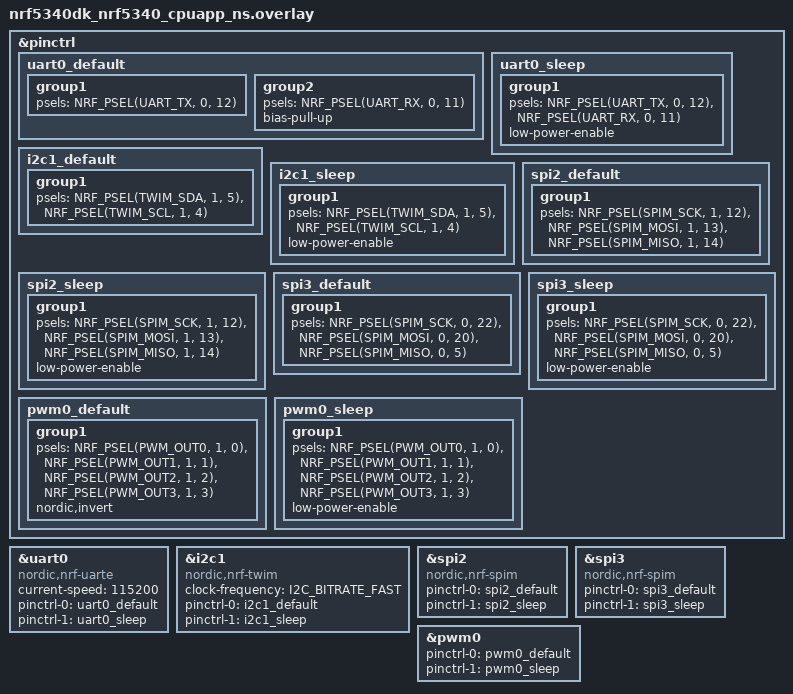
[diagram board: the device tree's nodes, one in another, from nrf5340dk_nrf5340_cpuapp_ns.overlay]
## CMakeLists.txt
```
#
# Copyright (c) 2019 Nordic Semiconductor ASA
#
# SPDX-License-Identifier: LicenseRef-BSD-5-Clause-Nordic
#

cmake_minimum_required(VERSION 3.20.0)

if (EXISTS "${CMAKE_CURRENT_SOURCE_DIR}/spm.conf")
  set(spm_CONF_FILE
    prj.conf
    ${CMAKE_CURRENT_LIST_DIR}/spm.conf
  )
endif()

if (EXISTS "${CMAKE_CURRENT_SOURCE_DIR}/mcuboot.conf")
  set(mcuboot_CONF_FILE
    prj.conf
    ${CMAKE_CURRENT_LIST_DIR}/mcuboot.conf
  )
endif()

find_package(Zephyr REQUIRED HINTS $ENV{ZEPHYR_BASE})
project(E2)
zephyr_compile_definitions(PROJECT_NAME=${PROJECT_NAME})

# NORDIC SDK APP START
target_sources(app PRIVATE src/main.c)
# NORDIC SDK APP END

# Include source directory
target_include_directories(app PRIVATE src)
target_include_directories(app PRIVATE $ENV{ZEPHYR_BASE}/subsys/fs/nvs)

# Application directories
add_subdirectory(src/datetime)
add_subdirectory(src/font)
add_subdirectory(src/image)
add_subdirectory(src/lcd)
add_subdirectory(src/key)
add_subdirectory(src/settings)
add_subdirectory(src/inner_flash)
add_subdirectory(src/external_flash)
add_subdirectory(src/uart_ble)
add_subdirectory(src/screen)
add_subdirectory(src/pmu)
add_subdirectory(src/codetrans)
add_subdirectory(src/communicate)
add_subdirectory(src/ucs2)
add_subdirectory(src/logger)

add_subdirectory_ifdef(CONFIG_PPG_SUPPORT src/ppg)
add_subdirectory_ifdef(CONFIG_ECG_SUPPORT src/ecg)
add_subdirectory_ifdef(CONFIG_BUZZER_SUPPORT src/buzzer)
add_subdirectory_ifdef(CONFIG_WATCHDOG src/watchdog)
add_subdirectory_ifdef(CONFIG_FACTORY_TEST_SUPPORT src/factory_test)
```

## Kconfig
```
#
# Copyright (c) 2018 Nordic Semiconductor ASA
#
# SPDX-License-Identifier: LicenseRef-BSD-5-Clause-Nordic
#
choice LOG_MODE
	default LOG_MODE_IMMEDIATE
endchoice

menu "GPS"
config GPS_SUPPORT
	bool "gps support"
	default n
endmenu #GPS

menu "GNSS"
choice
	default GNSS_SAMPLE_MODE_CONTINUOUS
	prompt "Select GNSS operation mode"

config GNSS_SAMPLE_MODE_CONTINUOUS
	bool "Continuous tracking"

config GNSS_SAMPLE_MODE_PERIODIC
	bool "Periodic fixes"

config GNSS_SAMPLE_MODE_TTFF_TEST
	bool "Time-to-first-fix (TTFF) test mode"
	select GNSS_SAMPLE_NMEA_ONLY
endchoice

if GNSS_SAMPLE_MODE_PERIODIC
config GNSS_SAMPLE_PERIODIC_INTERVAL
	int "Fix interval for periodic fixes"
	range 10 65535
	default 120
	help
	  Fix interval (in seconds) for periodic fixes.
config GNSS_SAMPLE_PERIODIC_TIMEOUT
	int "Fix timeout for periodic fixes"
	range 0 65535
	default 120
	help
	  Fix timeout (in seconds) for periodic fixes.
	  If set to zero, GNSS is allowed to run indefinitely until a valid PVT estimate is produced.
endif # GNSS_SAMPLE_MODE_PERIODIC

if GNSS_SAMPLE_MODE_TTFF_TEST
config GNSS_SAMPLE_MODE_TTFF_TEST_COLD_START
	bool "Delete GNSS data before each start (cold start)"
	help
	  When enabled, deletes all stored data from GNSS to force a cold start every time GNSS is started.
config GNSS_SAMPLE_MODE_TTFF_TEST_INTERVAL
	int "Time to wait between TTFF tests in seconds"
	range 1 604800
	default 120
endif # GNSS_SAMPLE_MODE_TTFF_TEST

config GNSS_SAMPLE_NMEA_ONLY
	bool "Output only NMEA strings"
	help
	  Outputs only NMEA strings from the GNSS.

choice
	default GNSS_SAMPLE_ANTENNA_ONBOARD
	prompt "Select which antenna to use for GNSS"

config GNSS_SAMPLE_ANTENNA_ONBOARD
	bool "Use onboard antenna"

config GNSS_SAMPLE_ANTENNA_EXTERNAL
	bool "Use external antenna"
endchoice

config GNSS_SAMPLE_AT_MAGPIO
	string "AT%XMAGPIO command"
	# default "AT\%XMAGPIO=1,0,0,1,1,1574,1577" if BOARD_NRF9160DK_NRF9160_NS
	# default "AT\%XMAGPIO=1,1,1,7,1,746,803,2,698,748,2,1710,2200,3,824,894,4,880,960,5,791,849,7,1565,1586" if BOARD_THINGY91_NRF9160_NS
	default "AT\%XMAGPIO=1,1,1,7,1,746,803,2,698,748,2,1710,2200,3,824,894,4,880,960,5,791,849,7,1565,1586"
	help
	  Defines the AT%XMAGPIO command to be sent to GNSS module. Leave
	  empty if this command should not be sent.

config GNSS_SAMPLE_AT_COEX0
	string "AT%XCOEX0 command"
	# default "AT\%XCOEX0=1,1,1565,1586" if (BOARD_NRF9160DK_NRF9160_NS || BOARD_THINGY91_NRF9160_NS) && GNSS_SAMPLE_ANTENNA_ONBOARD
	# default "AT\%XCOEX0" if (BOARD_NRF9160DK_NRF9160_NS || BOARD_THINGY91_NRF9160_NS) && GNSS_SAMPLE_ANTENNA_EXTERNAL
	default "AT\%XCOEX0=1,1,1565,1586"
	help
	  Defines the AT%XCOEX0 command to be sent to GNSS module. Leave
	  empty if this command should not be sent.

endmenu #GNSS

choice
	default GNSS_SAMPLE_ASSISTANCE_NONE
	prompt "Select whether GNSS assistance is used or not"

config GNSS_SAMPLE_ASSISTANCE_NONE
	bool "Assistance not used"

config GNSS_SAMPLE_ASSISTANCE_NRF_CLOUD
	bool "Use nRF Cloud A-GPS or P-GPS"
	select NRF_CLOUD_REST
	imply NRF_CLOUD_AGPS
	select MODEM_JWT
	select MODEM_INFO
	select DATE_TIME

config GNSS_SAMPLE_ASSISTANCE_SUPL
	bool "Use SUPL A-GPS"
	select SUPL_CLIENT_LIB

config GNSS_SAMPLE_ASSISTANCE_MINIMAL
	bool "Use factory almanac, LTE network time and MCC based location"
	select GNSS_SAMPLE_LTE_ON_DEMAND
	select SETTINGS
	select FCB
	select FLASH
	select FLASH_MAP
endchoice

if !GNSS_SAMPLE_ASSISTANCE_NONE
config GNSS_SAMPLE_LTE_ON_DEMAND
	bool "LTE is activated only when needed to fetch A-GPS data"
	depends on !NRF_CLOUD_PGPS
	help
	  Activates LTE only when it is needed to fetch A-GPS data. This is not supported when
	  P-GPS is enabled.

endif # !GNSS_SAMPLE_ASSISTANCE_NONE

if GNSS_SAMPLE_ASSISTANCE_SUPL
config GNSS_SAMPLE_SUPL_HOSTNAME
	string "SUPL server hostname"
	default "supl.google.com"
	help
	  SUPL server hostname.

config GNSS_SAMPLE_SUPL_PORT
	int "SUPL server port number"
	range 0 65535
	default 7276
	help
	  SUPL server port number.
endif # GNSS_SAMPLE_ASSISTANCE_SUPL

if GNSS_SAMPLE_MODE_CONTINUOUS
choice
	default GNSS_SAMPLE_POWER_SAVING_DISABLED
	prompt "Select GNSS power saving mode (duty-cycling)"

config GNSS_SAMPLE_POWER_SAVING_DISABLED
	bool "No power saving"

config GNSS_SAMPLE_POWER_SAVING_MODERATE
	bool "Power saving without significant performance degradation"

config GNSS_SAMPLE_POWER_SAVING_HIGH
	bool "Power saving with acceptable performance degradation"
endchoice
endif # GNSS_SAMPLE_MODE_CONTINUOUS

config GNSS_SAMPLE_LOW_ACCURACY
	bool "Allow low accuracy fixes"
	help
	  Allows fixes with lower accuracy.

if GNSS_SAMPLE_ASSISTANCE_MINIMAL && GNSS_SAMPLE_LOW_ACCURACY
config GNSS_SAMPLE_ASSISTANCE_REFERENCE_ALT
	int "Reference altitude for 3-sat first fix in meters"
	range -32767 32767
	default -32767
	help
	  Reference altitude for 3-sat first fix in meters above the reference ellipsoid surface.
	  The default value -32767 implies that reference altitude is not injected.
endif # GNSS_SAMPLE_ASSISTANCE_MINIMAL && GNSS_SAMPLE_LOW_ACCURACY

menu "MQTT simple sample"
config APPLICATION_WORKQUEUE_STACK_SIZE
	int "Application workqueue stack size"
	default 1024

config APPLICATION_WORKQUEUE_PRIORITY
	int "Application workqueue priority"
	default SYSTEM_WORKQUEUE_PRIORITY
	
config MQTT_LOG_PUB_TOPIC
	string "MQTT log publish topic"
	default "device/e2/pushlog"

config MQTT_PUB_TOPIC
	string "MQTT publish topic"
	default "device/e2/pushdata"

config MQTT_SUB_TOPIC
	string "MQTT subscribe topic"
	default "my/subscribe/topic"

config MQTT_CLIENT_ID
	string "MQTT Client ID"
	default "my-client-id"

config MQTT_USER_NAME
	string "MQTT user name"
	default "admin123"
	
config MQTT_PASSWORD
	string "MQTT password"
	default "admin123"

config MQTT_DOMESTIC_BROKER_HOSTNAME
	string "MQTT broker hostname"
	default "mqtt.eclipse.org"

config MQTT_DOMESTIC_BROKER_PORT
	int "MQTT broker port"
	default 1883
	
config MQTT_FOREIGN_BROKER_HOSTNAME
	string "MQTT broker hostname"
	default "mqtt.eclipse.org"

config MQTT_FOREIGN_BROKER_PORT
	int "MQTT broker port"
	default 1883

config MQTT_MESSAGE_BUFFER_SIZE
	int "MQTT message buffer size"
	default 128

config MQTT_PAYLOAD_BUFFER_SIZE
	int "MQTT payload buffer size"
	default 128

config SEC_TAG
	int "Security tag to use for the connection"
	default 16842753

config PEER_VERIFY
	int "Peer verify parameter for mqtt_client"
	default 1
	help
		Set to 0 for VERIFY_NONE, 1 for VERIFY_OPTIONAL, and 2 for VERIFY_REQUIRED.

config MODEM_AUTO_REQUEST_POWER_SAVING_FEATURES
	bool "Auto request power saving features"
	default y

config LTE_EDRX_ENABLE
	bool "Enable LTE enhanced Discontinuous Reception"

config LTE_RAI_ENABLE
	bool "Enable LTE Release Assistance Indication"
endmenu

menu "WATCH DOG"
config WATCHDOG_TIMEOUT_MSEC
	int "Watchdog timeout in milliseconds"
	default 10000
endmenu

menu "ANIMATION"
config ANIMATION_SUPPORT
	bool "animation support"
	default n
endmenu #ANIMATION

menu "ANIMATION"
config ANIMATION_SUPPORT
	bool "animation support"
	default n
endmenu #ANIMATION

menu "TOUCH"
config TOUCH_SUPPORT
	bool "touch support"
	default n
endmenu #TOUCH

menu "WIFI"
config WIFI_SUPPORT
	bool "wifi support"
	default n
endmenu #WIFI

menu "PPG"
config PPG_SUPPORT
	bool "ppg support"
	default n
endmenu #PPG

menu "ECG"
config ECG_SUPPORT
	bool "ecg support"
	default n
endmenu #ECG

menu "IMU"
config IMU_SUPPORT
	bool "imu support"
	default n
config STEP_SUPPORT
	bool "step support"
	default n		
config SLEEP_SUPPORT
	bool "sleep support"
	default n		
config FALL_DETECT_SUPPORT
	bool "fall detect support"
	default n		
endmenu #IMU

menu "AUDIO"
config AUDIO_SUPPORT
	bool "ppg support"
	default n
endmenu #AUDIO

menu "BLE"
config BLE_SUPPORT
	bool "ble support"
	default n
endmenu #BLE

menu "BUZZER"
config BUZZER_SUPPORT
	bool "buzzer support"
	default n
endmenu #BUZZER

menu "SYNC"
config SYNC_SUPPORT
	bool "sync support"
	default n
endmenu #SYNC

menu "TEMPERATURE"
config TEMP_SUPPORT
	bool "temperature support"
	default n
endmenu #TEMPERATURE

menu "CRC"
config CRC_SUPPORT
	bool "crc check support"
	default n
endmenu #CRC

menu "DATA_DOWNLOAD"
config DATA_DOWNLOAD_SUPPORT
	bool "data download support"
	default n
config DATA_DOWNLOAD_HOST_CN
	string "Download host name(cn)"	
config DATA_DOWNLOAD_HOST_HK
	string "Download host name(hk)"	
# IMG	
config IMG_DATA_UPDATE
	bool "img update support"
	default n
config IMG_DATA_DOWNLOAD_FILE
	string "The file to download"

# FONT
config FONT_DATA_UPDATE
	bool "font update support"
	default n
config FONT_DATA_DOWNLOAD_FILE
	string "The file to download"

# PPG
config PPG_DATA_UPDATE
	bool "ppg update support"
	default n
config PPG_DATA_DOWNLOAD_FILE
	string "The file to download"

config USE_HTTPS
	bool
	prompt "Use HTTPS for download"
	depends on DOWNLOAD_CLIENT_TLS	
endmenu #DATA_DOWNLOAD 

menu "IMG_UPDATE"
config DL_TARGET_UI
	bool "img ui update support"
	default n
endmenu #IMG_UPDATE

menu "FOTA_MQTT"
config FOTA_DOWNLOAD_HOST_CN
	string "Download host name(cn)"
config FOTA_DOWNLOAD_HOST_HK
	string "Download host name(hk)"

config FOTA_DOWNLOAD_FILE
	string "The file to download"

config APPLICATION_VERSION
	int "Application version"
	default 1

config USE_HTTPS
	bool
	prompt "Use HTTPS for download"
	depends on DOWNLOAD_CLIENT_TLS
endmenu #FOTA_MQTT

menu "BAT CODE"
config BARCODE_SUPPORT
	bool "bar code support"
	default n
endmenu #BAT CODE

menu "QR CODE"
config QRCODE_SUPPORT
	bool "qr code support"
	default n
endmenu #QR CODE

menu "WRIST CHECK"
config WRIST_CHECK_SUPPORT
	bool "wrist check support"
	default n
endmenu #WRIST CHECK

menu "FACTORY_TEST"
config FACTORY_TEST_SUPPORT
	bool "factory test support"
	default n
endmenu #FACTORY_TEST_SUPPORT

menu "FAST_KEY"
config FAST_KEY_SUPPORT
	bool "fast key support"
	default n
endmenu #FAST_KEY_SUPPORT

menu "ALARM_SUPPORT"
config ALARM_SUPPORT
	bool "alarm support"
	default n
endmenu #ALARM_SUPPORT

menu "Zephyr Kernel"
source "Kconfig.zephyr"
endmenu

module = APPLICATION_MODULE
module-str = Application module
source "subsys/logging/Kconfig.template.log_config"
```

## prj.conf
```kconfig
#
# Copyright (c) 2022 Nordic Semiconductor ASA
#
# SPDX-License-Identifier: LicenseRef-Nordic-5-Clause
#
# General config
CONFIG_NEWLIB_LIBC=y
CONFIG_NEWLIB_LIBC_FLOAT_PRINTF=y
CONFIG_ASSERT=y
CONFIG_REBOOT=y
CONFIG_GPIO=y
CONFIG_TRUSTED_EXECUTION_NONSECURE=y

# Log
CONFIG_LOG=n
CONFIG_USE_SEGGER_RTT=y
CONFIG_LOG_BACKEND_RTT=y
CONFIG_LOG_BACKEND_UART=n
CONFIG_LOG_DEFAULT_LEVEL=4
CONFIG_LOG_MODE_OVERFLOW=y
CONFIG_LOG_BACKEND_RTT_MODE_DROP=y
CONFIG_LOG_BACKEND_SHOW_COLOR=n
CONFIG_LOG_BACKEND_FORMAT_TIMESTAMP=n

# PinCtrl
CONFIG_PINCTRL=y
CONFIG_PINCTRL_NRF=y

# watch dog
CONFIG_WATCHDOG=y
CONFIG_WATCHDOG_TIMEOUT_MSEC=10000

# Fuel gauge
CONFIG_NRF_FUEL_GAUGE=y

# NVS
CONFIG_FLASH=y
CONFIG_FLASH_PAGE_LAYOUT=y
CONFIG_NVS=y
CONFIG_NVS_LOG_LEVEL_DBG=y
CONFIG_MPU_ALLOW_FLASH_WRITE=y

# Console
CONFIG_CONSOLE_SUBSYS=n
CONFIG_CONSOLE_HANDLER=n
CONFIG_CONSOLE_GETCHAR=n
CONFIG_CONSOLE=y
CONFIG_RTT_CONSOLE=y
CONFIG_UART_CONSOLE=n


# Library for buttons and LEDs
CONFIG_DK_LIBRARY=y

# Heap and stacks
CONFIG_HEAP_MEM_POOL_SIZE=16384
CONFIG_MAIN_STACK_SIZE=8192
CONFIG_SYSTEM_WORKQUEUE_STACK_SIZE=2048
CONFIG_HW_STACK_PROTECTION=y

# PWM
CONFIG_PWM=y

# SPI
CONFIG_SPI=y

# I2C
CONFIG_I2C=y

# UART
CONFIG_SERIAL=y
CONFIG_UART_INTERRUPT_DRIVEN=y

# ECG
CONFIG_ECG_SUPPORT=y

# BLE
CONFIG_BLE_SUPPORT=n

# BUZZER
CONFIG_BUZZER_SUPPORT=y

# CRC Check
CONFIG_CRC_SUPPORT=n

# DEVICE POWER MANAGEMENT
CONFIG_PM_DEVICE=y

# Facotry test
CONFIG_FACTORY_TEST_SUPPORT=n
CONFIG_ENTROPY_GENERATOR=y
CONFIG_TEST_RANDOM_GENERATOR=y
```

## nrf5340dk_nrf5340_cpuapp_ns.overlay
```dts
/* SPDX-License-Identifier: Apache-2.0 */

&pinctrl
{
	uart0_default: uart0_default
	{
		group1
		{
			psels = <NRF_PSEL(UART_TX, 0, 12)>;
		};
		group2
		{
			psels = <NRF_PSEL(UART_RX, 0, 11)>;
			bias-pull-up;
		};
	};

	uart0_sleep: uart0_sleep
	{
		group1
		{
			psels = <NRF_PSEL(UART_TX, 0, 12)>,
							<NRF_PSEL(UART_RX, 0, 11)>;
			low-power-enable;
		};
	};
	
	i2c1_default: i2c1_default
	{
		group1
		{
			psels = <NRF_PSEL(TWIM_SDA, 1, 5)>,
							<NRF_PSEL(TWIM_SCL, 1, 4)>;
		};
	};

	i2c1_sleep: i2c1_sleep
	{
		group1
		{
			psels = <NRF_PSEL(TWIM_SDA, 1, 5)>,
							<NRF_PSEL(TWIM_SCL, 1, 4)>;
			low-power-enable;
		};
	};
	
	spi2_default: spi2_default
	{
		group1
		{
			psels = <NRF_PSEL(SPIM_SCK,  1, 12)>,
							<NRF_PSEL(SPIM_MOSI, 1, 13)>,
							<NRF_PSEL(SPIM_MISO, 1, 14)>;
		};
	};

	spi2_sleep: spi2_sleep
	{
		group1
		{
			psels = <NRF_PSEL(SPIM_SCK,  1, 12)>,
							<NRF_PSEL(SPIM_MOSI, 1, 13)>,
							<NRF_PSEL(SPIM_MISO, 1, 14)>;
			low-power-enable;
		};
	};
	
	spi3_default: spi3_default
	{
		group1
		{
			psels = <NRF_PSEL(SPIM_SCK,  0, 22)>,
							<NRF_PSEL(SPIM_MOSI, 0, 20)>,
							<NRF_PSEL(SPIM_MISO, 0, 5)>;
		};
	};

	spi3_sleep: spi3_sleep
	{
		group1
		{
			psels = <NRF_PSEL(SPIM_SCK,  0, 22)>,
							<NRF_PSEL(SPIM_MOSI, 0, 20)>,
							<NRF_PSEL(SPIM_MISO, 0, 5)>;
			low-power-enable;
		};
	};
	
	pwm0_default: pwm0_default
	{
		group1
		{
			psels = <NRF_PSEL(PWM_OUT0,  1, 0)>,
							<NRF_PSEL(PWM_OUT1,  1, 1)>,
							<NRF_PSEL(PWM_OUT2,  1, 2)>,
							<NRF_PSEL(PWM_OUT3,  1, 3)>;
			nordic,invert;
		};
	};

	pwm0_sleep: pwm0_sleep
	{
		group1
		{
			psels = <NRF_PSEL(PWM_OUT0,  1, 0)>,
							<NRF_PSEL(PWM_OUT1,  1, 1)>,
							<NRF_PSEL(PWM_OUT2,  1, 2)>,
							<NRF_PSEL(PWM_OUT3,  1, 3)>;
			low-power-enable;
		};
	};
};


&uart0{
	compatible = "nordic,nrf-uarte";
	status = "okay";
	current-speed = <115200>;
	pinctrl-0 = <&uart0_default>;
	pinctrl-1 = <&uart0_sleep>;
	pinctrl-names = "default", "sleep";
};

&i2c1{
	compatible = "nordic,nrf-twim";
	status = "okay";
	clock-frequency = <I2C_BITRATE_FAST>;
	pinctrl-0 = <&i2c1_default>;
	pinctrl-1 = <&i2c1_sleep>;
	pinctrl-names = "default", "sleep";
};

&spi2{
	compatible = "nordic,nrf-spim";
	status = "okay";
	pinctrl-0 = <&spi2_default>;
	pinctrl-1 = <&spi2_sleep>;
	pinctrl-names = "default", "sleep";
};

&spi3{
	compatible = "nordic,nrf-spim";
	status = "okay";
	pinctrl-0 = <&spi3_default>;
	pinctrl-1 = <&spi3_sleep>;
	pinctrl-names = "default", "sleep";
};

&pwm0{
	status = "okay";
	pinctrl-0 = <&pwm0_default>;
	pinctrl-1 = <&pwm0_sleep>;
	pinctrl-names = "default", "sleep";
};
```

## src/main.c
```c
/*
* Copyright (c) 2019 Nordic Semiconductor ASA
*
* SPDX-License-Identifier: LicenseRef-BSD-5-Clause-Nordic
*/

#include <zephyr/kernel.h>
#include <zephyr/device.h>
#include <stdio.h>
#include <zephyr/sys/printk.h>
#include <power/reboot.h>
#include <zephyr/drivers/spi.h>
#include <zephyr/drivers/gpio.h>
#include <dk_buttons_and_leds.h>
#include "datetime.h"
#include "inner_flash.h"
#include "external_flash.h"
#include "uart_ble.h"
#include "settings.h"
#include "pmu.h"
#include "codetrans.h"
#ifdef CONFIG_WATCHDOG
#include "watchdog.h"
#endif
#include "logger.h"

static bool sys_pwron_completed_flag = false;

static void modem_init(void)
{
	//nrf_modem_lib_init(NORMAL_MODE);
	//boot_write_img_confirmed();
}

void system_init(void)
{
	k_sleep(K_MSEC(500));//xb test 2022-03-11 启动时候延迟0.5S,等待其他外设完全启动

	modem_init();

	InitSystemSettings();

#ifdef CONFIG_PPG_SUPPORT
	//PPG_i2c_off();
#endif
	//pmu_init();
	//key_init();
	//flash_init();
	
#ifdef CONFIG_PPG_SUPPORT	
	//PPG_init();
#endif
#ifdef CONFIG_ECG_SUPPORT
	ECG_init();
#endif
#ifdef CONFIG_BUZZER_SUPPORT
	buzzer_init();
#endif
	//ble_init();
	//LogInit();
}

void work_init(void)
{
	if(IS_ENABLED(CONFIG_WATCHDOG))
	{
		watchdog_init_and_start(&k_sys_work_q);
	}
}

bool system_is_completed(void)
{
	return sys_pwron_completed_flag;
}

void system_init_completed(void)
{
	if(!sys_pwron_completed_flag)
		sys_pwron_completed_flag = true;
}

/***************************************************************************
* 描  述 : main函数 
* 入  参 : 无 
* 返回值 : int 类型
**************************************************************************/
int main(void)
{
	work_init();
	system_init();
	
//	test_show_string();
//	test_show_image();
//	test_show_color();
//	test_show_stripe();
//	test_nvs();
//	test_flash();
//	test_uart_ble();
//	test_sensor();
//	test_show_digital_clock();
//	test_sensor();
//	test_pmu();
//	test_crypto();
//	test_imei_for_qr();
//	test_tp();
//	test_gps_on();
//	test_nb();
//	test_i2c();
//	test_bat_soc();
//	test_notify();
//	test_wifi();
//	LogInit();

	while(1)
	{
		//KeyMsgProcess();
		//TimeMsgProcess();
		//PMUMsgProcess();
	#ifdef CONFIG_PPG_SUPPORT	
		//PPGMsgProcess();
	#endif
	#ifdef CONFIG_ECG_SUPPORT
		ECGMsgProcess();
	#endif
	#ifdef CONFIG_BUZZER_SUPPORT
		BuzzerMsgProcess();
	#endif
		//SettingsMsgPorcess();
		//UartMsgProc();
	#ifdef CONFIG_FACTORY_TEST_SUPPORT
		//FactoryTestProccess();
	#endif
		//LogMsgProcess();
		//system_init_completed();
		//k_cpu_idle();
	}
}
```
